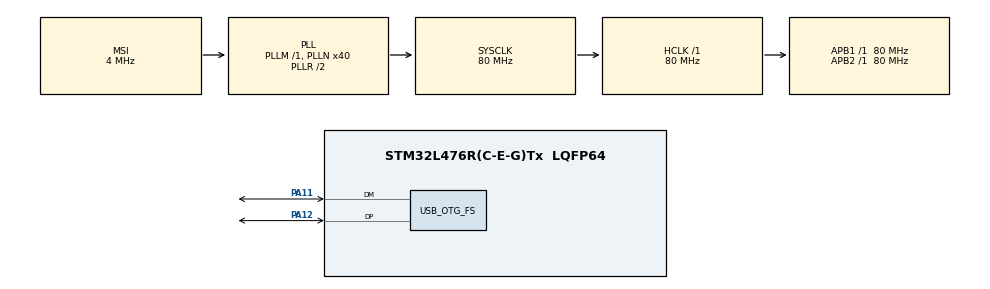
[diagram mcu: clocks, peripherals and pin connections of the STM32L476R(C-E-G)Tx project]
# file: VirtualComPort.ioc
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Mcu.Family=STM32L4
Mcu.Name=STM32L476R(C-E-G)Tx
Mcu.Package=LQFP64
NVIC.OTG_FS_IRQn=true\:0\:0\:false\:false\:true\:false\:true
NVIC.PriorityGroup=NVIC_PRIORITYGROUP_4
PA11.Mode=Device_Only
PA11.Signal=USB_OTG_FS_DM
PA12.Mode=Device_Only
PA12.Signal=USB_OTG_FS_DP
ProjectManager.HeapSize=0x200
ProjectManager.StackSize=0x400
ProjectManager.TargetToolchain=TrueSTUDIO
RCC.ADCFreq_Value=48000000
RCC.AHBFreq_Value=80000000
RCC.APB1Freq_Value=80000000
RCC.APB1TimFreq_Value=80000000
RCC.APB2Freq_Value=80000000
RCC.APB2TimFreq_Value=80000000
RCC.CortexFreq_Value=80000000
RCC.HCLKFreq_Value=80000000
RCC.HSE_VALUE=8000000
RCC.HSI_VALUE=16000000
RCC.LSE_VALUE=32768
RCC.MSI_VALUE=4000000
RCC.PLLN=40
RCC.PLLSAI1N=24
RCC.SYSCLKFreq_VALUE=80000000
RCC.SYSCLKSource=RCC_SYSCLKSOURCE_PLLCLK
RCC.USBFreq_Value=48000000
RCC.VCOOutputFreq_Value=160000000
USB_DEVICE.CLASS_NAME_FS=CDC
USB_DEVICE.VirtualMode=Cdc
USB_DEVICE.VirtualModeFS=Cdc_FS
USB_OTG_FS.VirtualMode=Device_Only
VP_USB_DEVICE_VS_USB_DEVICE_CDC_FS.Mode=CDC_FS
board=custom

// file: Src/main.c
/* USER CODE BEGIN Header */
/**
  ******************************************************************************
  * @file           : main.c
  * @brief          : Main program body
  ******************************************************************************
  * @attention
  *
  * <h2><center>&copy; Copyright (c) 2019 STMicroelectronics.
  * All rights reserved.</center></h2>
  *
  * This software component is licensed by ST under Ultimate Liberty license
  * SLA0044, the "License"; You may not use this file except in compliance with
  * the License. You may obtain a copy of the License at:
  *                             www.st.com/SLA0044
  *
  ******************************************************************************
  */
/* USER CODE END Header */

#include "main.h"
#include "usb_device.h"
#include "usbd_cdc_if.h"

/* USER CODE BEGIN Includes */
uint8_t i=0;
char str_tx[21];
char str_rx[21];
uint8_t CDC_Transmit_FS(uint8_t* Buf, uint16_t Len);
/* USER CODE END Includes */

void SystemClock_Config(void);
static void MX_GPIO_Init(void);

int main(void)
{
  /* USER CODE BEGIN 1 */
	sprintf(str_tx,"12345");
  /* USER CODE END 1 */

  /* MCU Configuration--------------------------------------------------------*/

  /* Reset of all peripherals, Initializes the Flash interface and the Systick. */
  HAL_Init();

  /* Configure the system clock */
  SystemClock_Config();

  /* Initialize all configured peripherals */
  MX_GPIO_Init();
  MX_USB_DEVICE_Init();

  /* Infinite loop */
  while (1)
  {
      CDC_Transmit_FS((unsigned char*)str_tx, strlen(str_tx));

      HAL_Delay(500);
  }
}

void SystemClock_Config(void)
{
  RCC_OscInitTypeDef RCC_OscInitStruct = {0};
  RCC_ClkInitTypeDef RCC_ClkInitStruct = {0};
  RCC_PeriphCLKInitTypeDef PeriphClkInit = {0};

  /** Initializes the CPU, AHB and APB busses clocks
  */
  RCC_OscInitStruct.OscillatorType = RCC_OSCILLATORTYPE_MSI;
  RCC_OscInitStruct.MSIState = RCC_MSI_ON;
  RCC_OscInitStruct.MSICalibrationValue = 0;
  RCC_OscInitStruct.MSIClockRange = RCC_MSIRANGE_6;
  RCC_OscInitStruct.PLL.PLLState = RCC_PLL_ON;
  RCC_OscInitStruct.PLL.PLLSource = RCC_PLLSOURCE_MSI;
  RCC_OscInitStruct.PLL.PLLM = 1;
  RCC_OscInitStruct.PLL.PLLN = 40;
  RCC_OscInitStruct.PLL.PLLP = RCC_PLLP_DIV7;
  RCC_OscInitStruct.PLL.PLLQ = RCC_PLLQ_DIV2;
  RCC_OscInitStruct.PLL.PLLR = RCC_PLLR_DIV2;
  if (HAL_RCC_OscConfig(&RCC_OscInitStruct) != HAL_OK)
  {
    Error_Handler();
  }
  /** Initializes the CPU, AHB and APB busses clocks
  */
  RCC_ClkInitStruct.ClockType = RCC_CLOCKTYPE_HCLK|RCC_CLOCKTYPE_SYSCLK
                              |RCC_CLOCKTYPE_PCLK1|RCC_CLOCKTYPE_PCLK2;
  RCC_ClkInitStruct.SYSCLKSource = RCC_SYSCLKSOURCE_PLLCLK;
  RCC_ClkInitStruct.AHBCLKDivider = RCC_SYSCLK_DIV1;
  RCC_ClkInitStruct.APB1CLKDivider = RCC_HCLK_DIV1;
  RCC_ClkInitStruct.APB2CLKDivider = RCC_HCLK_DIV1;

  if (HAL_RCC_ClockConfig(&RCC_ClkInitStruct, FLASH_LATENCY_4) != HAL_OK)
  {
    Error_Handler();
  }
  PeriphClkInit.PeriphClockSelection = RCC_PERIPHCLK_USB;
  PeriphClkInit.UsbClockSelection = RCC_USBCLKSOURCE_PLLSAI1;
  PeriphClkInit.PLLSAI1.PLLSAI1Source = RCC_PLLSOURCE_MSI;
  PeriphClkInit.PLLSAI1.PLLSAI1M = 1;
  PeriphClkInit.PLLSAI1.PLLSAI1N = 24;
  PeriphClkInit.PLLSAI1.PLLSAI1P = RCC_PLLP_DIV7;
  PeriphClkInit.PLLSAI1.PLLSAI1Q = RCC_PLLQ_DIV2;
  PeriphClkInit.PLLSAI1.PLLSAI1R = RCC_PLLR_DIV2;
  PeriphClkInit.PLLSAI1.PLLSAI1ClockOut = RCC_PLLSAI1_48M2CLK;
  if (HAL_RCCEx_PeriphCLKConfig(&PeriphClkInit) != HAL_OK)
  {
    Error_Handler();
  }
  /** Configure the main internal regulator output voltage
  */
  if (HAL_PWREx_ControlVoltageScaling(PWR_REGULATOR_VOLTAGE_SCALE1) != HAL_OK)
  {
    Error_Handler();
  }
}

static void MX_GPIO_Init(void)
{

  /* GPIO Ports Clock Enable */
  __HAL_RCC_GPIOA_CLK_ENABLE();

}

void Error_Handler(void)
{
}

/************************ (C) COPYRIGHT STMicroelectronics *****END OF FILE****/
